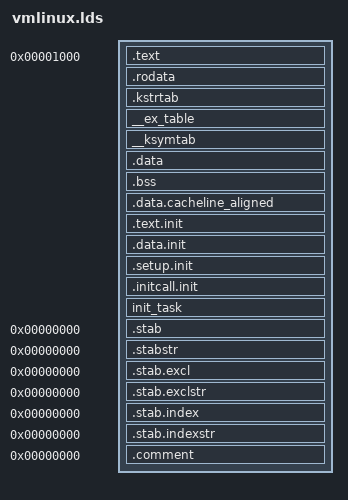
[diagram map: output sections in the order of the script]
/* ld script to make m68k Linux kernel */
OUTPUT_FORMAT("elf32-m68k", "elf32-m68k", "elf32-m68k")
OUTPUT_ARCH(m68k)
ENTRY(_start)
SECTIONS
{
  . = 0x1000;
  _text = .;			/* Text and read-only data */
  .text : {
	*(.text)
	*(.fixup)
	*(.gnu.warning)
	} = 0x4e75
  .rodata : { *(.rodata) *(.rodata.*) }
  .kstrtab : { *(.kstrtab) }

  . = ALIGN(16);		/* Exception table */
  __start___ex_table = .;
  __ex_table : { *(__ex_table) }
  __stop___ex_table = .;

  __start___ksymtab = .;	/* Kernel symbol table */
  __ksymtab : { *(__ksymtab) }
  __stop___ksymtab = .;

  _etext = .;			/* End of text section */

  .data : {			/* Data */
	*(.data)
	CONSTRUCTORS
	}

  .bss : { *(.bss) }		/* BSS */

  . = ALIGN(16);
  .data.cacheline_aligned : { *(.data.cacheline_aligned) }

  _edata = .;			/* End of data section */

  . = ALIGN(4096);		/* Init code and data */
  __init_begin = .;
  .text.init : { *(.text.init) }
  .data.init : { *(.data.init) }
  . = ALIGN(16);
  __setup_start = .;
  .setup.init : { *(.setup.init) }
  __setup_end = .;
  __initcall_start = .;
  .initcall.init : { *(.initcall.init) }
  __initcall_end = .;
  . = ALIGN(8192);
  __init_end = .;

  init_task : { *(init_task) }	/* The initial task and kernel stack */

  _end = . ;

  /* Stabs debugging sections.  */
  .stab 0 : { *(.stab) }
  .stabstr 0 : { *(.stabstr) }
  .stab.excl 0 : { *(.stab.excl) }
  .stab.exclstr 0 : { *(.stab.exclstr) }
  .stab.index 0 : { *(.stab.index) }
  .stab.indexstr 0 : { *(.stab.indexstr) }
  .comment 0 : { *(.comment) }
}
